# CY8C4xxx register map
File version: 0.1
Registers are 8-bit, read-write, no defined reset value unless marked. A register's access mark holds for its fields unless they carry their own. Offsets are from the block's base; [hi:lo] are bit positions; {n}, {i} and the like mark numbered series.

## CM0 — Cortex-M0 System Bus (ARM PPB Peripherals)
Base 0xE0000000
0x1FD0 DWT_PID4 32-bit — Watchpoint Unit CoreSight ROM Table Peripheral ID #4
  [31:0] VALUE ro — Peripheral ID #4
{0x1FE0+4i} DWT_PID{i} 32-bit (i=0..3) — Watchpoint Unit CoreSight ROM Table Peripheral ID #{i}
  [31:0] VALUE ro — Peripheral ID #{i}
{0x1FF0+4i} DWT_CID{i} 32-bit (i=0..3) — Watchpoint Unit CoreSight ROM Table Component ID #{i}
  [31:0] VALUE ro — Component ID #{i}
0x2FD0 BP_PID4 32-bit — Breakpoint Unit CoreSight ROM Table Peripheral ID #4
  [31:0] VALUE ro — Peripheral ID #4
{0x2FE0+4i} BP_PID{i} 32-bit (i=0..3) — Breakpoint Unit CoreSight ROM Table Peripheral ID #{i}
  [31:0] VALUE ro — Peripheral ID #{i}
{0x2FF0+4i} BP_CID{i} 32-bit (i=0..3) — Breakpoint Unit CoreSight ROM Table Component ID #{i}
  [31:0] VALUE ro — Component ID #{i}
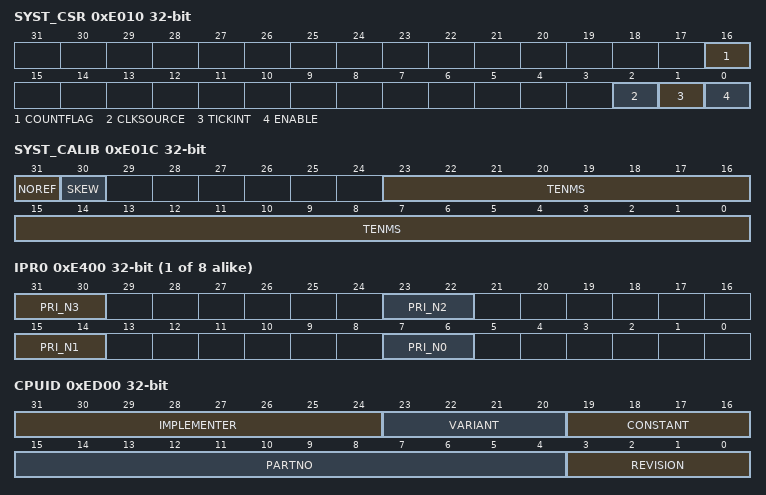
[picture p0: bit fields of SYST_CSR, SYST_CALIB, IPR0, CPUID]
0xE010 SYST_CSR 32-bit — Systick Control & Status
  [16] COUNTFLAG ro — Indicates whether the counter has counted to 0 since the last read of this register:?0 timer has not counted to 0.?1 timer has counted to 0.?COUNTFLAG is set to 1 by a count transition from 1 to 0.?COUNTFLAG is cleared to 0 by a read of this register, and by any write to the Current Value register.
  [2] CLKSOURCE — Indicates the SysTick clock source:?0 SysTick uses the optional external reference clock.?1 SysTick uses the processor clock.?If no external clock is provided, this bit reads as one and ignores writes.
  [1] TICKINT — Indicates whether counting to 0 causes the status of the SysTick exception to change to pending:?0 count to 0 does not affect the SysTick exception status.?1 count to 0 changes the SysTick exception status to pending.?Changing the value of the counter to 0 by writing zero to the SysTick Current Value register to 0 never changes the status of the SysTick exception.
  [0] ENABLE — Indicates the enabled status of the SysTick counter:?0 counter is disabled.?1 counter is operating.
0xE014 SYST_RVR 32-bit — Systick Reload Value
  [23:0] RELOAD — The value to load into the SYST_CVR register when the counter reaches 0.
0xE018 SYST_CVR 32-bit — SysTick Current Value
  [23:0] CURRENT — Current counter value.?This is the value of the counter at the time it is sampled.
0xE01C SYST_CALIB 32-bit — SysTick Calibration Value
  [31] NOREF ro — Indicates whether the IMPLEMENTATION DEFINED reference clock is provided:?0 the reference clock is implemented.?1 the reference clock is not implemented.?When this bit is 1, the CLKSOURCE bit of the SYST_CSR register is forced to 1 and cannot be cleared to 0.
  [30] SKEW ro — Indicates whether the 10ms calibration value is exact:?0 10ms calibration value is exact.?1 10ms calibration value is inexact, because of the clock frequency.
  [23:0] TENMS ro — Optionally, holds a reload value to be used for 10ms (100Hz) timing, subject to system clock skew errors. If this field is zero, the calibration value is not known.
0xE100 ISER 32-bit — Interrupt Set-Enable Register
  [31:0] SETENA write-once — Enables, or reads the enabled state of one or more interrupts. Each bit corresponds to the same numbered interrupt.
0xE180 ICER 32-bit — Interrupt Clear Enable Register
  [31:0] CLRENA write-once — Disables, or reads the enabled state of one or more interrupts. Each bit corresponds to the same numbered interrupt.
0xE200 ISPR 32-bit — Interrupt Set-Pending Register
  [31:0] SETPEND write-once — Changes the state of one or more interrupts to pending. Each bit corresponds to the same numbered interrupt.
0xE280 ICPR 32-bit — Interrupt Clear-Pending Register
  [31:0] CLRPEND write-once — Changes the state of one or more interrupts to not pending. Each bit corresponds to the same numbered interrupt.
{0xE400+4i} IPR{i} 32-bit (i=0..7) — Interrupt Priority Registers
  [31:30] PRI_N3 — Priority of interrupt number N+3.
  [23:22] PRI_N2 — Priority of interrupt number N+2.
  [15:14] PRI_N1 — Priority of interrupt number N+1.
  [7:6] PRI_N0 — Priority of interrupt number N.
0xED00 CPUID 32-bit
  [31:24] IMPLEMENTER ro — Implementer code for ARM.
  [23:20] VARIANT ro — Implementation defined. In ARM implementations this is the major revision number n in the rn part of the rnpn revision status, Product revision status on page xii.
  [19:16] CONSTANT ro — Indicates the architecture, ARMv6-M
  [15:4] PARTNO ro — Indicates part number, Cortex-M0
  [3:0] REVISION ro — Indicates revision. In ARM implementations this is the minor revision number n in the pn part of the rnpn revision status, see Product revision status on page xii. For release r0p0.
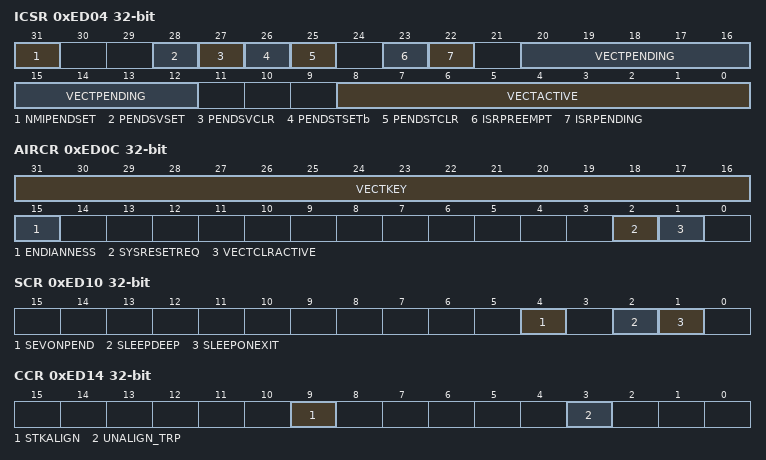
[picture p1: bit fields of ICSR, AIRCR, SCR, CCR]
0xED04 ICSR 32-bit — Interrupt Control State Register
  [31] NMIPENDSET write-once — Activates an NMI exception or reads back the current state.?Because NMI is the highest priority exception, it activates as soon as it is registered.
  [28] PENDSVSET write-once — Sets a pending PendSV interrupt or reads back the current state. Use this normally to request a context switch. Writing PENDSVSET and PENDSVCLR to '1' concurrently is UNPREDICTABLE.
  [27] PENDSVCLR write-once — Clears a pending PendSV interrupt.
  [26] PENDSTSETb write-once — Sets a pending SysTick or reads back the current state. Writing PENDSTSET and PENDSTCLR to '1' concurrently is UNPREDICTABLE.
  [25] PENDSTCLR write-once — Clears a pending SysTick, whether set here or by the timer hardware.
  [23] ISRPREEMPT ro — Indicates whether a pending exception will be serviced on exit from debug halt state.
  [22] ISRPENDING ro — Indicates if an external configurable, NVIC generated, interrupt is pending.
  [20:12] VECTPENDING ro — The exception number for the highest priority pending exception. 0= No pending exceptions.?The pending state includes the effect of memory-mapped enable and mask registers. It does not include the PRIMASK special-purpose register qualifier.
  [8:0] VECTACTIVE ro — The exception number for the current executing exception. 0= Thread mode. This is the same value as IPSR[8:0]
0xED0C AIRCR 32-bit — Application Interrupt and Reset Control Register
  [31:16] VECTKEY — Vector Key. The value 0x05FA must be written to this register, otherwise the register write is UNPREDICTABLE. Readback value is UNKNOWN.
  [15] ENDIANNESS ro — Indicates the memory system data endianness:?0 little endian?1 big endian.?See Endian support on page A3-44 for more information.
  [2] SYSRESETREQ write-once — System Reset Request. Writing 1 to this bit asserts a signal to request a reset by the external system. This will cause a full system reset of the CPU and all other components in the device. See Reset management on page B1-240 for more information.
  [1] VECTCLRACTIVE write-once — Clears all active state information for fixed and configurable?exceptions. The effect of writing a 1 to this bit if the processor is not halted in Debug state is UNPREDICTABLE.
0xED10 SCR 32-bit — System Control Register
  [4] SEVONPEND — Determines whether an interrupt transition from inactive state to pending state is a wakeup event:?0: transitions from inactive to pending are not wakeup events.?1: transitions from inactive to pending are wakeup events.?See WFE on page A6-197 for more information.
  [2] SLEEPDEEP — An implementation can use this bit to select DeepSleep/Hibernate power modes upon execution of WFI/WFE:?0: Select Sleep mode?1: Select DeepSleep/Hibernate (depends on PWR_CONTROL.HIBERNATE)
  [1] SLEEPONEXIT — Determines whether, on an exit from an ISR that returns to the base level of execution priority, the processor enters a sleep state:?0 do not enter sleep state.?1 enter sleep state.?See Power management on page B1-240 for more information.
0xED14 CCR 32-bit — Configuration and Control Register
  [9] STKALIGN ro — 1: On exception entry, the SP used prior to the exception is adjusted to be 8-byte aligned and the context to restore it is saved. The SP is restored on the associated exception return.
  [3] UNALIGN_TRP ro — 1: unaligned word and halfword accesses generate a HardFault exception.
0xED1C SHPR2 32-bit — System Handler Priority Register 2
  [31:30] PRI_11 — Priority of system handler 11, SVCall
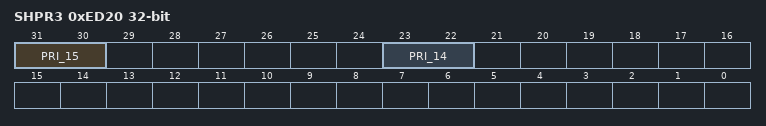
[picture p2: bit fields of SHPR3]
0xED20 SHPR3 32-bit — System Handler Priority Register 3
  [31:30] PRI_15 — Priority of system handler 15, SysTick
  [23:22] PRI_14 — Priority of system handler 14, PendSV
0xED24 SHCSR 32-bit — System Handler Control and State Register
  [15] SVCALLPENDED — 0 SVCall is not pending.?1 SVCall is pending.?This bit reflects the pending state on a read, and updates the pending state, to the value written, on a write. (Pending state bits are set to 1 when an exception occurs, and are cleared to 0 when an exception becomes active.)
0xEFD0 SCS_PID4 32-bit — System Control Space ROM Table Peripheral ID #4
  [31:0] VALUE ro — Peripheral ID #4
{0xEFE0+4i} SCS_PID{i} 32-bit (i=0..3) — System Control Space ROM Table Peripheral ID #{i}
  [31:0] VALUE ro — Peripheral ID #{i}
{0xEFF0+4i} SCS_CID{i} 32-bit (i=0..3) — System Control Space ROM Table Component ID #{i}
  [31:0] VALUE ro — Component ID #{i}
0xFF000 ROM_SCS 32-bit — CM0 CoreSight ROM Table Peripheral #0
  [31:0] VALUE ro — Offset to SCS ROM Table
0xFF004 ROM_DWT 32-bit — CM0 CoreSight ROM Table Peripheral #1
  [31:0] VALUE ro — Offset to DWT ROM Table
0xFF008 ROM_BPU 32-bit — CM0 CoreSight ROM Table Peripheral #2
  [31:0] VALUE ro — Offset to BPU ROM Table
0xFF00C ROM_END 32-bit — CM0 CoreSight ROM Table End Marker
  [31:0] VALUE ro — End marker in peripheral list
0xFFFCC ROM_CSMT 32-bit — CM0 CoreSight ROM Table Memory Type
  [31:0] VALUE ro — Memory Type
0xFFFD0 ROM_PID4 32-bit — CM0 CoreSight ROM Table Peripheral ID #4
  [31:0] VALUE ro — Peripheral ID #4
{0xFFFE0+4i} ROM_PID{i} 32-bit (i=0..3) — CM0 CoreSight ROM Table Peripheral ID #{i}
  [31:0] VALUE ro — Peripheral ID #{i}
{0xFFFF0+4i} ROM_CID{i} 32-bit (i=0..3) — CM0 CoreSight ROM Table Component ID #{i}
  [31:0] VALUE ro — Component ID #{i}
